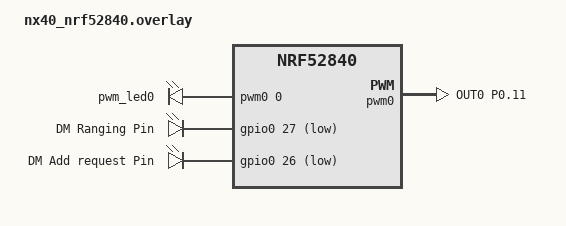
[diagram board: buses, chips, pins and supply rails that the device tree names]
/*
 * Copyright (c) 2023 Nordic Semiconductor ASA
 * Copyright (c) 2026 Korlinx
 *
 * SPDX-License-Identifier: LicenseRef-Nordic-5-Clause
 */

#include <zephyr/dt-bindings/gpio/gpio.h>
#include <zephyr/dt-bindings/pwm/pwm.h>

/ {
	chosen {
		ncs,dm-timer = &timer2;
	};

	pwmleds {
		compatible = "pwm-leds";

		pwm_led0: pwm_led_0 {
			pwms = <&pwm0 0 PWM_MSEC(20) PWM_POLARITY_INVERTED>;
		};
	};

	aliases {
		pwm-led0 = &pwm_led0;
	};

	dm_gpio {
		compatible = "gpio-leds";

		dm_ranging: dm-ranging {
			gpios = <&gpio0 27 GPIO_ACTIVE_LOW>;
			label = "DM Ranging Pin";
		};

		dm_add_request: dm-add-request {
			gpios = <&gpio0 26 GPIO_ACTIVE_LOW>;
			label = "DM Add request Pin";
		};
	};
};

&pinctrl {
	pwm0_default: pwm0_default {
		group1 {
			psels = <NRF_PSEL(PWM_OUT0, 0, 11)>;
		};
	};

	pwm0_sleep: pwm0_sleep {
		group1 {
			psels = <NRF_PSEL(PWM_OUT0, 0, 11)>;
			low-power-enable;
		};
	};
};

&pwm0 {
	status = "okay";
	pinctrl-0 = <&pwm0_default>;
	pinctrl-1 = <&pwm0_sleep>;
	pinctrl-names = "default", "sleep";
};
